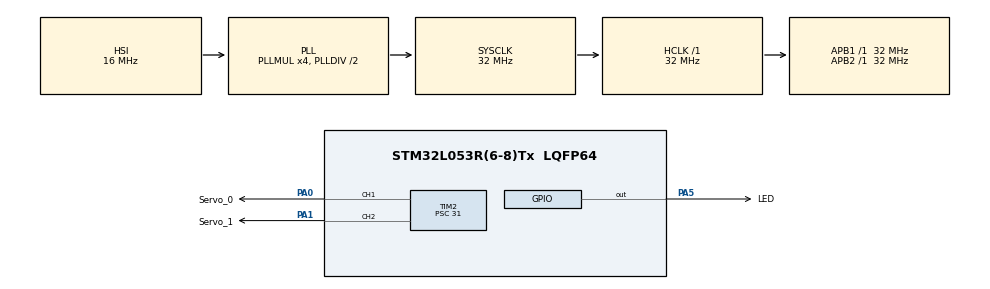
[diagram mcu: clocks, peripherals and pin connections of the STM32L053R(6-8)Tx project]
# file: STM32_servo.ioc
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Mcu.Family=STM32L0
Mcu.Name=STM32L053R(6-8)Tx
Mcu.Package=LQFP64
PA0.GPIO_Label=Servo_0
PA0.Signal=S_TIM2_CH1
PA1.GPIO_Label=Servo_1
PA1.Signal=S_TIM2_CH2
PA5.GPIO_Label=LED
PA5.Signal=GPIO_Output
ProjectManager.HeapSize=0x200
ProjectManager.StackSize=0x400
ProjectManager.TargetToolchain=SW4STM32
RCC.AHBFreq_Value=32000000
RCC.APB1Freq_Value=32000000
RCC.APB1TimFreq_Value=32000000
RCC.APB2Freq_Value=32000000
RCC.APB2TimFreq_Value=32000000
RCC.HCLKFreq_Value=32000000
RCC.HSE_VALUE=8000000
RCC.HSI16_VALUE=16000000
RCC.HSI48_VALUE=48000000
RCC.HSI_VALUE=16000000
RCC.LSE_VALUE=32768
RCC.MSI_VALUE=2097000
RCC.PLLMUL=RCC_PLLMUL_4
RCC.SYSCLKFreq_VALUE=32000000
RCC.SYSCLKSource=RCC_SYSCLKSOURCE_PLLCLK
RCC.VCOOutputFreq_Value=64000000
SH.S_TIM2_CH1.0=TIM2_CH1,PWM Generation1 CH1
SH.S_TIM2_CH2.0=TIM2_CH2,PWM Generation2 CH2
TIM2.Channel-PWM\ Generation1\ CH1=TIM_CHANNEL_1
TIM2.Channel-PWM\ Generation2\ CH2=TIM_CHANNEL_2
TIM2.CounterMode=TIM_COUNTERMODE_UP
TIM2.Period=20000
TIM2.Prescaler=31
TIM2.Pulse-PWM\ Generation1\ CH1=1000
TIM2.Pulse-PWM\ Generation2\ CH2=1000
VP_TIM2_VS_ClockSourceINT.Mode=Internal
board=STM32_servo

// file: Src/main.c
/* USER CODE BEGIN Header */
/**
  ******************************************************************************
  * @file           : main.c
  * @brief          : Main program body
  ******************************************************************************
  ** This notice applies to any and all portions of this file
  * that are not between comment pairs USER CODE BEGIN and
  * USER CODE END. Other portions of this file, whether
  * inserted by the user or by software development tools
  * are owned by their respective copyright owners.
  *
  * COPYRIGHT(c) 2019 STMicroelectronics
  *
  * Redistribution and use in source and binary forms, with or without modification,
  * are permitted provided that the following conditions are met:
  *   1. Redistributions of source code must retain the above copyright notice,
  *      this list of conditions and the following disclaimer.
  *   2. Redistributions in binary form must reproduce the above copyright notice,
  *      this list of conditions and the following disclaimer in the documentation
  *      and/or other materials provided with the distribution.
  *   3. Neither the name of STMicroelectronics nor the names of its contributors
  *      may be used to endorse or promote products derived from this software
  *      without specific prior written permission.
  *
  * THIS SOFTWARE IS PROVIDED BY THE COPYRIGHT HOLDERS AND CONTRIBUTORS "AS IS"
  * AND ANY EXPRESS OR IMPLIED WARRANTIES, INCLUDING, BUT NOT LIMITED TO, THE
  * IMPLIED WARRANTIES OF MERCHANTABILITY AND FITNESS FOR A PARTICULAR PURPOSE ARE
  * DISCLAIMED. IN NO EVENT SHALL THE COPYRIGHT HOLDER OR CONTRIBUTORS BE LIABLE
  * FOR ANY DIRECT, INDIRECT, INCIDENTAL, SPECIAL, EXEMPLARY, OR CONSEQUENTIAL
  * DAMAGES (INCLUDING, BUT NOT LIMITED TO, PROCUREMENT OF SUBSTITUTE GOODS OR
  * SERVICES; LOSS OF USE, DATA, OR PROFITS; OR BUSINESS INTERRUPTION) HOWEVER
  * CAUSED AND ON ANY THEORY OF LIABILITY, WHETHER IN CONTRACT, STRICT LIABILITY,
  * OR TORT (INCLUDING NEGLIGENCE OR OTHERWISE) ARISING IN ANY WAY OUT OF THE USE
  * OF THIS SOFTWARE, EVEN IF ADVISED OF THE POSSIBILITY OF SUCH DAMAGE.
  *
  ******************************************************************************
 *  Created on: 01.02.2019
 *		Author: Mateusz Salamon
 *		www.msalamon.pl
 *		mateusz@msalamon.pl
 *
 *      Website: https://msalamon.pl/nigdy-wiecej-multipleksowania-na-gpio!-max7219-w-akcji-cz-3/
 *      GitHub:  https://github.com/lamik/MAX7219_matrix_STM32_HAL
 */
/* USER CODE END Header */

#include "main.h"
#include "tim.h"
#include "gpio.h"

/* USER CODE BEGIN Includes */
#include "servo.h"
/* USER CODE END Includes */

/* USER CODE BEGIN PV */
/* Private variables ---------------------------------------------------------*/
uint16_t angle;
servo_t servo1, servo2;
/* USER CODE END PV */

void SystemClock_Config(void);
/* USER CODE BEGIN PFP */
/* Private function prototypes -----------------------------------------------*/

/* USER CODE END PFP */

int main(void)
{

  /* MCU Configuration--------------------------------------------------------*/

  /* Reset of all peripherals, Initializes the Flash interface and the Systick. */
  HAL_Init();

  /* Configure the system clock */
  SystemClock_Config();

  /* Initialize all configured peripherals */
  MX_GPIO_Init();
  MX_TIM2_Init();
  /* USER CODE BEGIN 2 */
  Servo_Init(&servo1, &htim2, TIM_CHANNEL_1);
  Servo_Init(&servo2, &htim2, TIM_CHANNEL_2);

//  uint8_t i = 0;
  /* USER CODE END 2 */

  /* Infinite loop */
  while (1)
  {

    /* USER CODE BEGIN 3 */

	  Servo_SetAngle(&servo1, 0);
	  Servo_SetAngle(&servo2, 90);
	  HAL_Delay(1000);

	  Servo_SetAngle(&servo1, 90);
	  Servo_SetAngle(&servo2, 180);
	  HAL_Delay(1000);

	  Servo_SetAngleFine(&servo1, 160.12);
	  Servo_SetAngleFine(&servo2, 34.84);
	  HAL_Delay(1000);

//	  Servo_SetAngle(&servo1, 90);

	  HAL_GPIO_TogglePin(LED_GPIO_Port, LED_Pin);
	  HAL_Delay(1000);
  }
  /* USER CODE END 3 */
}

void SystemClock_Config(void)
{
  RCC_OscInitTypeDef RCC_OscInitStruct = {0};
  RCC_ClkInitTypeDef RCC_ClkInitStruct = {0};

  /**Configure the main internal regulator output voltage
  */
  __HAL_PWR_VOLTAGESCALING_CONFIG(PWR_REGULATOR_VOLTAGE_SCALE1);
  /**Initializes the CPU, AHB and APB busses clocks
  */
  RCC_OscInitStruct.OscillatorType = RCC_OSCILLATORTYPE_HSI;
  RCC_OscInitStruct.HSIState = RCC_HSI_ON;
  RCC_OscInitStruct.HSICalibrationValue = RCC_HSICALIBRATION_DEFAULT;
  RCC_OscInitStruct.PLL.PLLState = RCC_PLL_ON;
  RCC_OscInitStruct.PLL.PLLSource = RCC_PLLSOURCE_HSI;
  RCC_OscInitStruct.PLL.PLLMUL = RCC_PLLMUL_4;
  RCC_OscInitStruct.PLL.PLLDIV = RCC_PLLDIV_2;
  if (HAL_RCC_OscConfig(&RCC_OscInitStruct) != HAL_OK)
  {
    Error_Handler();
  }
  /**Initializes the CPU, AHB and APB busses clocks
  */
  RCC_ClkInitStruct.ClockType = RCC_CLOCKTYPE_HCLK|RCC_CLOCKTYPE_SYSCLK
                              |RCC_CLOCKTYPE_PCLK1|RCC_CLOCKTYPE_PCLK2;
  RCC_ClkInitStruct.SYSCLKSource = RCC_SYSCLKSOURCE_PLLCLK;
  RCC_ClkInitStruct.AHBCLKDivider = RCC_SYSCLK_DIV1;
  RCC_ClkInitStruct.APB1CLKDivider = RCC_HCLK_DIV1;
  RCC_ClkInitStruct.APB2CLKDivider = RCC_HCLK_DIV1;

  if (HAL_RCC_ClockConfig(&RCC_ClkInitStruct, FLASH_LATENCY_1) != HAL_OK)
  {
    Error_Handler();
  }
}

void Error_Handler(void)
{
  while(1)
  {
  }
}

/************************ (C) COPYRIGHT STMicroelectronics *****END OF FILE****/
